# NUC123AN_v1 register map
File version: 1.0
Registers are 32-bit, read-write, reset 0x0 unless marked. A register's access mark holds for its fields unless they carry their own. Offsets are from the block's base; [hi:lo] are bit positions; {n}, {i} and the like mark numbered series.

## DMA_GCR — PDMA Register Map
Base 0x50008F00
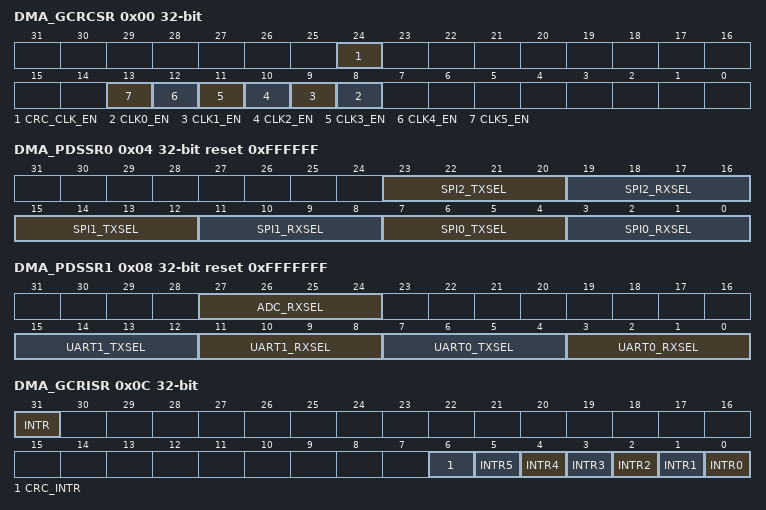
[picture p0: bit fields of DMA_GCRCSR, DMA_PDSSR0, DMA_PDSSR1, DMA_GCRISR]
0x00 DMA_GCRCSR — DMA Global Control Register
  [all] fields
    0=Disabled; 1=Enabled
  [24] CRC_CLK_EN — CRC Controller Clock Enable Control
  [n+8] CLK{n}_EN (n=0..5) — PDMA Controller Channel {n} Clock Enable Control
0x04 DMA_PDSSR0 reset 0xFFFFFF — DMA Service Selection Control Register 0
  [23:20] SPI2_TXSEL — PDMA SPI2 TX Selection. This filed defines which PDMA channel is connected to the on-chip peripheral SPI2 TX. Software can configure the TX channel setting by SPI2_TXSEL. The channel configuration is the same as SPI0_RXSEL field. Please refer to the explanation of SPI0_RXSEL.
  [19:16] SPI2_RXSEL — PDMA SPI2 RX Selection. This filed defines which PDMA channel is connected to the on-chip peripheral SPI2 RX. Software can configure the RX channel setting by SPI2_RXSEL. The channel configuration is the same as SPI0_RXSEL field. Please refer to the explanation of SPI0_RXSEL.
  [15:12] SPI1_TXSEL — PDMA SPI1 TX Selection. This filed defines which PDMA channel is connected to the on-chip peripheral SPI1 TX. Software can configure the TX channel setting by SPI1_TXSEL. The channel configuration is the same as SPI0_RXSEL field. Please refer to the explanation of SPI0_RXSEL.
  [11:8] SPI1_RXSEL — PDMA SPI1 RX Selection. This filed defines which PDMA channel is connected to the on-chip peripheral SPI1 RX. Software can configure the RX channel setting by SPI1_RXSEL. The channel configuration is the same as SPI0_RXSEL field. Please refer to the explanation of SPI0_RXSEL.
  [7:4] SPI0_TXSEL — PDMA SPI0 TX Selection. This filed defines which PDMA channel is connected to the on-chip peripheral SPI0 TX. Software can configure the TX channel setting by SPI0_TXSEL. The channel configuration is the same as SPI0_RXSEL field. Please refer to the explanation of SPI0_RXSEL.
  [3:0] SPI0_RXSEL — PDMA SPI0 RX Selection. This filed defines which PDMA channel is connected to the on-chip peripheral SPI0 RX. Software can change the channel RX setting by SPI0_RXSEL. 4'b0000: CH0. 4'b0001: CH1. 4'b0010: CH2. 4'b0011: CH3. 4'b0100: CH4. 4'b0101: CH5. Others: Reserved
0x08 DMA_PDSSR1 reset 0xFFFFFFF — DMA Service Selection Control Register 1
  [27:24] ADC_RXSEL — PDMA ADC RX Selection. This filed defines which PDMA channel is connected to the on-chip peripheral ADC RX. Software can configure the RX channel setting by ADC_RXSEL. The channel configuration is the same as UART0_RXSEL field. Please refer to the explanation of UART0_RXSEL.
  [15:12] UART1_TXSEL — PDMA UART1 TX Selection. This filed defines which PDMA channel is connected to the on-chip peripheral UART1 TX. Software can configure the TX channel setting by UART1_TXSEL. The channel configuration is the same as UART0_RXSEL field. Please refer to the explanation of UART0_RXSEL.
  [11:8] UART1_RXSEL — PDMA UART1 RX Selection. This filed defines which PDMA channel is connected to the on-chip peripheral UART1 RX. Software can configure the RX channel setting by UART1_RXSEL. The channel configuration is the same as UART0_RXSEL field. Please refer to the explanation of UART0_RXSEL.
  [7:4] UART0_TXSEL — PDMA UART0 TX Selection. This filed defines which PDMA channel is connected to the on-chip peripheral UART0 TX. Software can configure the TX channel setting by UART0_TXSEL. The channel configuration is the same as UART0_RXSEL field. Please refer to the explanation of UART0_RXSEL.
  [3:0] UART0_RXSEL — This filed defines which PDMA channel is connected to the on-chip peripheral UART0 RX. Software can change the channel RX setting by UART0_RXSEL. 4'b0000: CH0. 4'b0001: CH1. 4'b0010: CH2. 4'b0011: CH3. 4'b0100: CH4. 4'b0101: CH5. Others : Reserved
0x0C DMA_GCRISR ro — DMA Global Interrupt Status Register
  [31] INTR — Interrupt Pin Status. This bit is the Interrupt status of PDMA controller. Note: This bit is read only
  [6] CRC_INTR — Interrupt Pin Status of CRC Controller. This bit is the Interrupt status of CRC controller. Note: This bit is read only.
  [n] INTR{n} (n=0..5) — Interrupt Pin Status of Channel {n}. This bit is the Interrupt status of PDMA channel {n}. Note: This bit is read only.
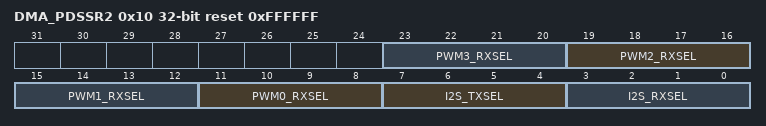
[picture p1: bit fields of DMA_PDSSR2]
0x10 DMA_PDSSR2 reset 0xFFFFFF — DMA Service Selection Control Register 2
  [4n+11:4n+8] PWM{n}_RXSEL (n=0..3) — PDMA PWM{n} RX Selection. This filed defines which PDMA channel is connected to the on-chip peripheral PWM{n} RX. Software can configure the RX channel setting by PWM{n}_RXSEL. The channel configuration is the same as I2S_RXSEL field. Please refer to the explanation of I2S_RXSEL.
  [7:4] I2S_TXSEL — PDMA I2S TX Selection. This filed defines which PDMA channel is connected to the on-chip peripheral I2S TX. Software can configure the TX channel setting by I2S_TXSEL. The channel configuration is the same as I2S_RXSEL field. Please refer to the explanation of I2S_RXSEL.
  [3:0] I2S_RXSEL — PDMA I2S RX Selection. This filed defines which PDMA channel is connected to the on-chip peripheral I2S RX. Software can change the channel RX setting by I2S_RXSEL. 4'b0000: CH0. 4'b0001: CH1. 4'b0010: CH2. 4'b0011: CH3. 4'b0100: CH4. 4'b0101: CH5. Others : Reserved
